# PIC32CM1216LS00032 device description
Architecture: CORTEX-M23; Family: PIC32CM; Series: PIC32CMLS00
Registers are 32-bit, read-write, reset 0x0 unless marked. A register's access mark holds for its fields unless they carry their own. Offsets are from the block's base; [hi:lo] are bit positions; {n}, {i} and the like mark numbered series.

## DIB — Debug Identification Block
Instances: DIB 0xE000EFB0, DIB_NS 0xE002EFB0
0x00 DLAR wo reset not defined — SCS Software Lock Access Register
  [31:0] KEY — Lock access control
    0xC5ACCE55=UNLOCK (Unlock key value)
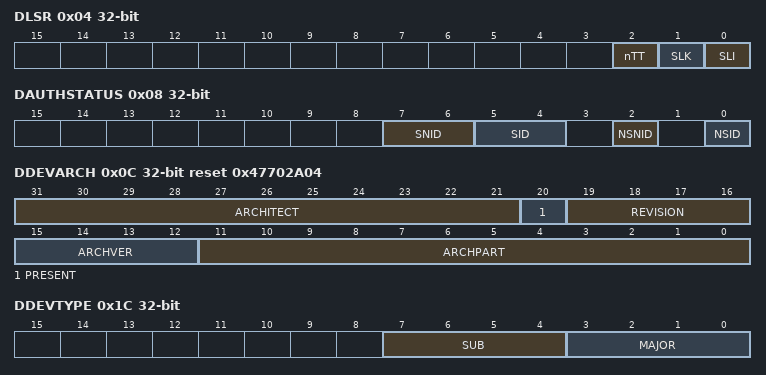
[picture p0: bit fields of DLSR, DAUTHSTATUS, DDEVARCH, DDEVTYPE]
0x04 DLSR ro reset not defined — SCS Software Lock Status Register
  [2] nTT — Not thirty-two bit
  [1] SLK — Software Lock status
  [0] SLI — Software Lock implemented
0x08 DAUTHSTATUS ro reset not defined — Debug Authentication Status Register
  [7:6] SNID
    0=NOSEC (Security Extension not implemented); 2=NO (Secure non-invasive debug prohibited); 3=YES (Secure non-invasive debug allowed)
  [5:4] SID
    0=NOSEC (Security Extension not implemented); 2=NO (Secure invasive debug prohibited); 3=YES (Secure invasive debug allowed)
  [2] NSNID
    2=NO (Non-secure non-invasive debug prohibited); 3=YES (Non-secure non-invasive debug allowed)
  [0] NSID
    2=NO (Non-secure invasive debug prohibited); 3=YES (Non-secure invasive debug allowed)
0x0C DDEVARCH ro reset 0x47702A04 — SCS Device Architecture Register
  [31:21] ARCHITECT
  [20] PRESENT — DEVARCH Present
  [19:16] REVISION
  [15:12] ARCHVER — Architecture Version
  [11:0] ARCHPART — Architecture Part
0x1C DDEVTYPE ro — SCS Device Type Register
  [7:4] SUB — Sub-type
  [3:0] MAJOR — Major type
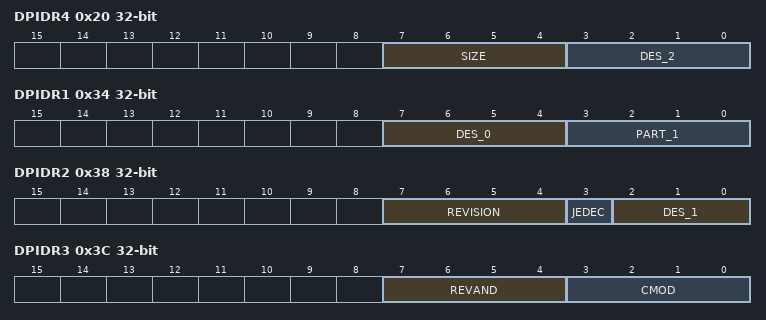
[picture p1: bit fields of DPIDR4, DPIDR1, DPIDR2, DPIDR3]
0x20 DPIDR4 ro reset not defined — SCS Peripheral Identification Register 4
  [7:4] SIZE — 4KB count
  [3:0] DES_2 — JEP106 continuation code
{0x10+4i} DPIDR{i} ro (i=5..7) — SCS Peripheral Identification Register {i}
0x30 DPIDR0 ro reset not defined — SCS Peripheral Identification Register 0
  [7:0] PART_0 — Part number bits[7:0]
0x34 DPIDR1 ro reset not defined — SCS Peripheral Identification Register 1
  [7:4] DES_0 — JEP106 identification code bits [3:0]
  [3:0] PART_1 — Part number bits[11:8]
0x38 DPIDR2 ro reset not defined — SCS Peripheral Identification Register 2
  [7:4] REVISION — Component revision
  [3] JEDEC — JEDEC assignee value is used
  [2:0] DES_1 — JEP106 identification code bits[6:4]
0x3C DPIDR3 ro reset not defined — SCS Peripheral Identification Register 3
  [7:4] REVAND
  [3:0] CMOD — Customer Modified
0x40 DCIDR0 ro reset 0xD — SCS Component Identification Register 0
  [7:0] PRMBL_0 — CoreSight component identification preamble
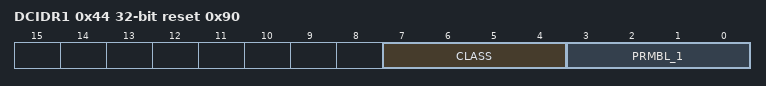
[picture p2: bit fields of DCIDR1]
0x44 DCIDR1 ro reset 0x90 — SCS Component Identification Register 1
  [7:4] CLASS — CoreSight component class
  [3:0] PRMBL_1 — CoreSight component identification preamble
0x48 DCIDR2 ro reset 0x5 — SCS Component Identification Register 2
  [7:0] PRMBL_2 — CoreSight component identification preamble
0x4C DCIDR3 ro reset 0xB1 — SCS Component Identification Register 3
  [7:0] PRMBL_3 — CoreSight component identification preamble

## DMAC_DESCRIPTOR — Direct Memory Access Controller
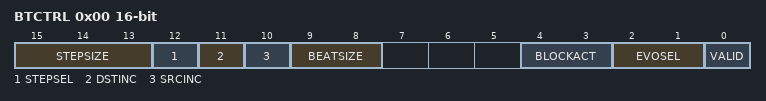
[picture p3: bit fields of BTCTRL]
0x00 BTCTRL 16-bit — Block Transfer Control
  [15:13] STEPSIZE — Address Increment Step Size
    0=Next ADDR = ADDR + (Beat Size in byte) * 1; 1=X2 (Next ADDR = ADDR + (Beat Size in byte) * 2); 2=X4 (Next ADDR = ADDR + (Beat Size in byte) * 4); 3=X8 (Next ADDR = ADDR + (Beat Size in byte) * 8); 4=X16 (Next ADDR = ADDR + (Beat Size in byte) * 16); 5=X32 (Next ADDR = ADDR + (Beat Size in byte) * 32); 6=X64 (Next ADDR = ADDR + (Beat Size in byte) * 64); 7=X128 (Next ADDR = ADDR + (Beat Size in byte) * 128)
  [12] STEPSEL — Step Selection
    0=DST (Step size settings apply to the destination address); 1=SRC (Step size settings apply to the source address)
  [11] DSTINC — Destination Address Increment Enable
  [10] SRCINC — Source Address Increment Enable
  [9:8] BEATSIZE
    0=BYTE (8-bit bus transfer); 1=HWORD (16-bit bus transfer); 2=WORD (32-bit bus transfer)
  [4:3] BLOCKACT — Block Action
    0=NOACT (Channel will be disabled if it is the last block transfer in the transaction); 1=INT (Channel will be disabled if it is the last block transfer in the transaction and block interrupt); 2=SUSPEND (Channel suspend operation is completed); 3=BOTH (Both channel suspend operation and block interrupt)
  [2:1] EVOSEL — Event Output Selection
    0=DISABLE (Event generation disabled); 1=BLOCK (Event strobe when block transfer complete); 3=BEAT (Event strobe when beat transfer complete)
  [0] VALID — Descriptor Valid
0x02 BTCNT 16-bit reset not defined — Block Transfer Count
0x04 SRCADDR reset not defined — Block Transfer Source Address
  [31:0] SRCADDR — Transfer Source Address
0x08 DSTADDR reset not defined — Block Transfer Destination Address
  [31:0] DSTADDR — Transfer Destination Address
0x0C DESCADDR reset not defined — Next Descriptor Address

## Notices in the file
Copyright (c) 2022 Microchip Technology Inc.
SPDX-License-Identifier: Apache-2.0
Licensed under the Apache License, Version 2.0 (the "License");
you may not use this file except in compliance with the License.
You may obtain a copy of the License at
http://www.apache.org/licenses/LICENSE-2.0
Unless required by applicable law or agreed to in writing, software
distributed under the License is distributed on an "AS IS" BASIS,
WITHOUT WARRANTIES OR CONDITIONS OF ANY KIND, either express or implied.
See the License for the specific language governing permissions and
limitations under the License.
